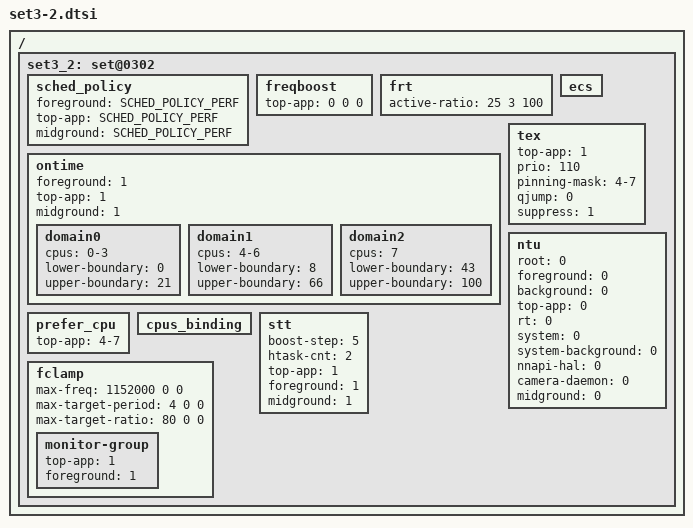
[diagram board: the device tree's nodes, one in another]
/ {
	/* game mode - app boost */
	set3_2: set@0302{
		/* schedudling policy */
		sched_policy {
			foreground 		= <SCHED_POLICY_PERF>;
			top-app			= <SCHED_POLICY_PERF>;
			midground       = <SCHED_POLICY_PERF>;
		};

		freqboost {
			top-app = <0 0 0>;
		};

		frt {	   			/* LIT MED BIG */
			active-ratio 		= < 25   3   100>;
		};

		ontime {
			foreground = <1>;
			top-app = <1>;
			midground = <1>;

			domain0 {
				cpus = "0-3";
				lower-boundary = <0>;
				upper-boundary = <21>;
			};

			domain1 {
				cpus = "4-6";
				lower-boundary = <8>;
				upper-boundary = <66>;
			};

			domain2 {
				cpus = "7";
				lower-boundary = <43>;
				upper-boundary = <100>;
			};
		};

		ecs { };

		tex {
			top-app = <1>;
			prio = <110>;
			pinning-mask = "4-7";
			qjump = <0>;
			suppress = <1>;
		};

		ntu {
			root = <0>;
			foreground = <0>;
			background = <0>;
			top-app = <0>;
			rt = <0>;
			system = <0>;
			system-background = <0>;
			nnapi-hal = <0>;
			camera-daemon = <0>;
			midground = <0>;
		};

		prefer_cpu {
			top-app = "4-7";
		};

		cpus_binding { };

		stt {
			boost-step = <5>;
			htask-cnt = <2>;
			top-app = <1>;
			foreground = <1>;
			midground = <1>;
		};

		fclamp {
			max-freq = <1152000 0 0>;
			max-target-period = <4 0 0>;
			max-target-ratio = <80 0 0>;

			monitor-group {
				top-app = <1>;
				foreground = <1>;
			};
		};
	};
};
